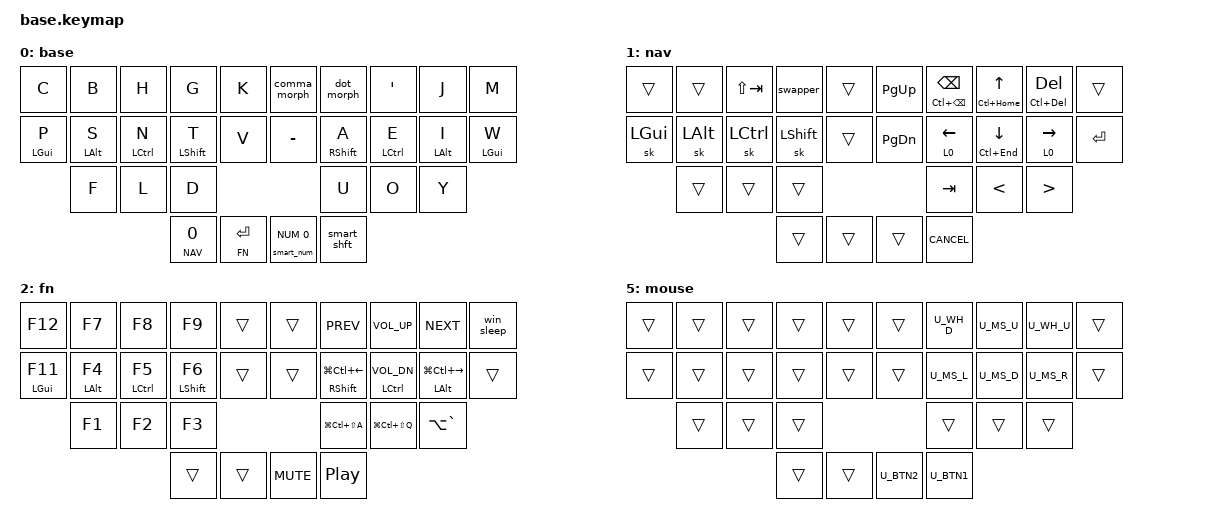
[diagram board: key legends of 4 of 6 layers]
#include <behaviors.dtsi>
#include <dt-bindings/zmk/keys.h>
#if CONFIG_WIRELESS
    #include <dt-bindings/zmk/bt.h>
    #define _BT_SEL_KEYS_ &bt BT_SEL 0 &bt BT_SEL 1 &bt BT_SEL 2 &bt BT_SEL 3 &bt BT_CLR
#else
    #define _BT_SEL_KEYS_ &trans &trans &trans &trans &trans
#endif

#include "../zmk-nodefree-config/helper.h"
// #include "../zmk-nodefree-config/international_chars/greek.dtsi"
// #include "../zmk-nodefree-config/international_chars/german.dtsi"

#define DEF 0
#define NAV 1
#define FN 2
#define NUM 3
#define SYS 4
#define UC 5
#define MOUSE 6

// #include "combos.dtsi"  // requires layer aliases
#include "mouse.dtsi"
#include "extra_keys.h"

#define XXX &none
#define ___ &trans

/* Global settings */

#define QUICK_TAP_MS 175

&sk {  // sticky-key config
    release-after-ms = <900>;  // release after 0.6s
    quick-release;             // no double capitalization when rolling keys
};

&sl {  // sticky-layer config
    ignore-modifiers;          // allow chording sticky mods & layers
};

&lt {  // layer-tap config
    flavor = "balanced";
    tapping-term-ms = <200>;
    quick-tap-ms = <QUICK_TAP_MS>;
};

/* Homerow mods */

#define KEYS_L LT0 LT1 LT2 LT3 LT4 LM0 LM1 LM2 LM3 LM4 LB0 LB1 LB2  // left hand
#define KEYS_R RT0 RT1 RT2 RT3 RT4 RM0 RM1 RM2 RM3 RM4 RB0 RB1 RB2  // right hand
#define THUMBS LH1 LH0 RH0 RH1                                      // thumbs

#define MAKE_HRM(NAME, HOLD, TAP, TRIGGER_POS) \
    ZMK_BEHAVIOR(NAME, hold_tap, \
        flavor = "balanced"; \
        tapping-term-ms = <280>; \
        quick-tap-ms = <QUICK_TAP_MS>; \
        require-prior-idle-ms = <150>; \
        bindings = <HOLD>, <TAP>; \
        hold-trigger-key-positions = <TRIGGER_POS>; \
        hold-trigger-on-release; \
    )
MAKE_HRM(hml, &kp, &kp, KEYS_R THUMBS)  // left-hand HRMs
MAKE_HRM(hmr, &kp, &kp, KEYS_L THUMBS)  // right-hand HRMs

MAKE_HRM(hml_repeat, &kp, &key_repeat, KEYS_R THUMBS)  // used for HRM-combo
MAKE_HRM(hmr_lpar_lt, &kp, &lpar_lt, KEYS_L THUMBS)    // "    "   "   "
MAKE_HRM(hmr_rpar_gt, &kp, &rpar_gt, KEYS_L THUMBS)    // "    "   "   "

/* Nav cluster */

// long-tap action on hold, short-tap action on all interrupts
#define MT_CORE \
    flavor = "tap-preferred"; \
    tapping-term-ms = <220>; \
    quick-tap-ms = <220>; \
    hold-trigger-key-positions = <0>;

&mt { MT_CORE };
ZMK_BEHAVIOR(mt_home, hold_tap, bindings = <&masked_home>, <&kp>; MT_CORE)
ZMK_BEHAVIOR(mt_end,  hold_tap,  bindings = <&masked_end>, <&kp>; MT_CORE)

#define NAV_LEFT  &mt_home 0   LEFT    // tap: left  | long-tap: beginning of line
#define NAV_RIGHT &mt_end 0    RIGHT   // tap: right | long-tap: end       of line
#define NAV_UP    &mt LC(HOME) UP      // tap: up    | long-tap: beginning of document
#define NAV_DOWN  &mt LC(END)  DOWN    // tap: down  | long-tap: end       of document
#define NAV_BSPC  &mt LC(BSPC) BSPC    // tap: bspc  | long-tap: delete word backward
#define NAV_DEL   &mt LC(DEL)  DEL     // tap: del   | long-tap: delete word forward

// mask CTRL when holding left/right to avoid accidental jumps to beginning/end of document
#define MASK_MODS(NAME, MODS, BINDING) \
    ZMK_BEHAVIOR(NAME, mod_morph, \
        bindings = <BINDING>, <BINDING>; \
        mods = <MODS>; \
    )
MASK_MODS(masked_home, (MOD_LCTL), &kp HOME)
MASK_MODS(masked_end,  (MOD_LCTL), &kp END)

/* Caps-word, num-word and smart-mouse */

// tap: sticky-shift | shift + tap/ double-tap: caps-word | hold: shift
ZMK_BEHAVIOR(smart_shft, mod_morph,
    bindings = <&sk LSHFT>, <&caps_word>;
    mods = <(MOD_LSFT)>;
)
&caps_word {  // mods deactivate caps-word, requires PR #1451
    /delete-property/ ignore-modifiers;
};

// tap: num-word | double-tap: sticky num-layer | hold: num-layer
#define SMART_NUM &smart_num NUM 0
ZMK_BEHAVIOR(smart_num, hold_tap,
    flavor = "balanced";
    tapping-term-ms = <200>;
    quick-tap-ms = <QUICK_TAP_MS>;
    bindings = <&mo>, <&num_dance>;
)
ZMK_BEHAVIOR(num_dance, tap_dance,
    tapping-term-ms = <200>;
    bindings = <&num_word>, <&sl NUM>;  // reverse this for sticky-num on single tap
)
&num_word {  // num-word, requires PR #1451
    layers = <NUM>;
    continue-list = <BSPC DEL DOT COMMA PLUS MINUS STAR FSLH EQUAL>;
};

// smart-mouse, requires PR #1366
ZMK_BEHAVIOR(smart_mouse, tri_state,
    bindings = <&tog MOUSE>, <&none>, <&tog MOUSE>;
    ignored-key-positions = <LT1 LT3 RT1 RT2 RT3 RM1 RM2 RM3 RH0 RH1>;
    ignored-layers = <MOUSE>;
)

/* Custom behaviors */

// Alt+Tab swapper, requires PR #1366
ZMK_BEHAVIOR(swapper, tri_state,
    bindings = <&kt LALT>, <&kp TAB>, <&kt LALT>;
    ignored-key-positions = <LT2>;
)

// Sticky layer + sticky shift (workaround for issue #1421)
ZMK_BEHAVIOR(sls, sticky_key,
    release-after-ms = <1000>;
    bindings = <&uc_shift>;
    ignore-modifiers;
)
ZMK_BEHAVIOR(uc_shift, macro,
    wait-ms = <0>;
    tap-ms = <1>;
    bindings = <&macro_press &mo UC &kp LSHFT>
             , <&macro_pause_for_release>
             , <&macro_release &mo UC &kp LSHFT>;
)

// reuse basic mod-morph scheme
#define SIMPLE_MORPH(NAME, MOD, BINDING1, BINDING2) \
    ZMK_BEHAVIOR(NAME, mod_morph, \
        mods = <(MOD_L ## MOD|MOD_R ## MOD)>; \
        bindings = <BINDING1>, <BINDING2>; \
    )

// tap: comma | shift + tap: semicolon | ctrl + shift + tap: <
SIMPLE_MORPH(comma_morph, SFT, &kp COMMA, &comma_inner_morph)
SIMPLE_MORPH(comma_inner_morph, CTL, &kp SEMICOLON, &kp LESS_THAN)

// tap: dot | shift + tap: colon | ctrl + shift + tap: >
SIMPLE_MORPH(dot_morph, SFT, &kp DOT, &dot_inner_morph)
SIMPLE_MORPH(dot_inner_morph, CTL, &kp COLON, &kp GREATER_THAN)

// tap: qmark | shift + tap: excl
SIMPLE_MORPH(qexcl, SFT, &kp QMARK, &kp EXCL)

// tap: left/right parenthesis | shft + tap: less-than/greater-than
SIMPLE_MORPH(lpar_lt, SFT, &kp LPAR, &kp LT)
SIMPLE_MORPH(rpar_gt, SFT, &kp RPAR, &kp GT)

// tap: space | shift + tap: dot -> space -> sticky shift | hold: activate layer
ZMK_BEHAVIOR(lt_spc, hold_tap,
    flavor = "balanced";
    tapping-term-ms = <200>;
    quick-tap-ms = <QUICK_TAP_MS>;
    bindings = <&mo>, <&spc_morph>;
)
SIMPLE_MORPH(spc_morph, SFT, &kp SPACE, &dot_spc)
ZMK_BEHAVIOR(dot_spc, macro,
    wait-ms = <0>;
    tap-ms = <5>;
    bindings = <&kp DOT &kp SPACE &sk LSHFT>;
)

// tap: backspace | lshft + tap: delete | rshft + tap: shift-delete
ZMK_BEHAVIOR(bs_del, mod_morph,
    bindings = <&kp BSPC>, <&kp DEL>;
    mods = <(MOD_LSFT|MOD_RSFT)>;
    keep-mods = <MOD_RSFT>;
)

// tap: copy | double-tap: cut
ZMK_BEHAVIOR(copy_cut, tap_dance,
    tapping-term-ms = <200>;
    bindings = <&kp LC(INS)>, <&kp LC(X)>;
)

// Windows sleep key
ZMK_BEHAVIOR(win_sleep, macro,
    wait-ms = <500>;
    tap-ms = <50>;
    bindings = <&kp LG(X) &kp U &kp S>;
)

// misc aliases
#define CANCEL      &kp K_CANCEL             // cancel caps-word, num-word and smart-mouse
#define DSK_PREV    &hmr RSHFT LG(LC(LEFT))  // previous desktop
#define DSK_NEXT    &hmr LALT LG(LC(RIGHT))  // next     desktop
#define PIN_WIN     &kp LG(LC(LS(Q)))        // pin window across desktops
#define PIN_APP     &kp LG(LC(LS(A)))        // pin application across desktops
#define DSK_MGR     &kp LA(GRAVE)            // desktop manager
#define VOL_DOWN    &hmr LCTRL C_VOL_DN

/* Keymap */

ZMK_CONDITIONAL_LAYER(FN NUM, SYS)  // FN + NUM --> SYS

ZMK_LAYER(base,
// ╭─────────────┬─────────────┬─────────────┬─────────────┬─────────────╮  ╭─────────────┬─────────────┬─────────────┬─────────────┬─────────────╮
     &kp C         &kp B         &kp H         &kp G         &kp K            &comma_morph  &dot_morph    &kp SQT       &kp J         &kp M        
// ├─────────────┼─────────────┼─────────────┼─────────────┼─────────────┤  ├─────────────┼─────────────┼─────────────┼─────────────┼─────────────┤
     &hml LGUI P   &hml LALT S   &hml LCTRL N  &hml LSHFT T  &kp V            &kp MINUS     &hmr RSHFT A  &hmr LCTRL E  &hmr LALT I   &hmr LGUI W  
// ├─────────────┼─────────────┼─────────────┼─────────────┼─────────────┤  ├─────────────┼─────────────┼─────────────┼─────────────┼─────────────┤
                   &kp F         &kp L         &kp D                                        &kp U         &kp O         &kp Y                      
// ╰─────────────┼─────────────┴─────────────┼─────────────┼─────────────┤  ├─────────────┼─────────────┼─────────────┴─────────────┴─────────────╯
                                               &lt_spc NAV 0 &lt FN RET       SMART_NUM     &smart_shft                                            
//                                           ╰─────────────┴─────────────╯  ╰─────────────┴─────────────╯                                          
)

ZMK_LAYER(nav,
// ╭─────────────┬─────────────┬─────────────┬─────────────┬─────────────╮  ╭─────────────┬─────────────┬─────────────┬─────────────┬─────────────╮
     ___           ___           &kp LS(TAB)   &swapper      ___              &kp PG_UP     NAV_BSPC      NAV_UP        NAV_DEL       ___          
// ├─────────────┼─────────────┼─────────────┼─────────────┼─────────────┤  ├─────────────┼─────────────┼─────────────┼─────────────┼─────────────┤
     &sk LGUI      &sk LALT      &sk LCTRL     &sk LSHFT     ___              &kp PG_DN     NAV_LEFT      NAV_DOWN      NAV_RIGHT     &kp RET      
// ├─────────────┼─────────────┼─────────────┼─────────────┼─────────────┤  ├─────────────┼─────────────┼─────────────┼─────────────┼─────────────┤
                   ___           ___           ___                                          &kp TAB       &kp LT        &kp GT                     
// ╰─────────────┼─────────────┴─────────────┼─────────────┼─────────────┤  ├─────────────┼─────────────┼─────────────┴─────────────┴─────────────╯
                                               ___           ___              ___           CANCEL                                                 
//                                           ╰─────────────┴─────────────╯  ╰─────────────┴─────────────╯                                          
)  

ZMK_LAYER(fn,
// ╭─────────────┬─────────────┬─────────────┬─────────────┬─────────────╮  ╭─────────────┬─────────────┬─────────────┬─────────────┬─────────────╮
     &kp F12       &kp F7        &kp F8        &kp F9        ___              ___           &kp C_PREV    &kp C_VOL_UP  &kp C_NEXT    &win_sleep   
// ├─────────────┼─────────────┼─────────────┼─────────────┼─────────────┤  ├─────────────┼─────────────┼─────────────┼─────────────┼─────────────┤
     &hml LGUI F11 &hml LALT F4  &hml LCTRL F5 &hml LSHFT F6 ___              ___           DSK_PREV      VOL_DOWN      DSK_NEXT      ___          
// ├─────────────┼─────────────┼─────────────┼─────────────┼─────────────┤  ├─────────────┼─────────────┼─────────────┼─────────────┼─────────────┤
                   &kp F1        &kp F2        &kp F3                                       PIN_APP       PIN_WIN       DSK_MGR             
// ╰─────────────┼─────────────┴─────────────┼─────────────┼─────────────┤  ├─────────────┼─────────────┼─────────────┴─────────────┴─────────────╯
                                               ___           ___              &kp C_MUTE    &kp C_PP                                               
//                                           ╰─────────────┴─────────────╯  ╰─────────────┴─────────────╯                                          
)

ZMK_LAYER(num,
// ╭─────────────┬─────────────┬─────────────┬─────────────┬─────────────╮  ╭─────────────┬─────────────┬─────────────┬─────────────┬─────────────╮
     ___           &kp N7        &kp N8        &kp N9        ___              ___           ___           ___           ___           ___          
// ├─────────────┼─────────────┼─────────────┼─────────────┼─────────────┤  ├─────────────┼─────────────┼─────────────┼─────────────┼─────────────┤
     &hml LGUI N0  &hml LALT N4  &hml LCTRL N5 &hml LSHFT N6 ___              ___           ___           ___           ___           ___          
// ├─────────────┼─────────────┼─────────────┼─────────────┼─────────────┤  ├─────────────┼─────────────┼─────────────┼─────────────┼─────────────┤
                   &kp N1        &kp N2        &kp N3                         ___           ___           ___           ___           
// ╰─────────────┼─────────────┴─────────────┼─────────────┼─────────────┤  ├─────────────┼─────────────┼─────────────┴─────────────┴─────────────╯
                                               ___           ___              ___           ___                                                    
//                                           ╰─────────────┴─────────────╯  ╰─────────────┴─────────────╯                                          
)

ZMK_LAYER(sys,
// ╭─────────────┬─────────────┬─────────────┬─────────────┬─────────────╮  ╭─────────────┬─────────────┬─────────────┬─────────────┬─────────────╮
                                _BT_SEL_KEYS_                                 ___           ___           ___           ___           ___          
// ├─────────────┼─────────────┼─────────────┼─────────────┼─────────────┤  ├─────────────┼─────────────┼─────────────┼─────────────┼─────────────┤
     ___           ___           ___           ___           &bootloader      &bootloader   ___           ___           ___           ___          
// ├─────────────┼─────────────┼─────────────┼─────────────┼─────────────┤  ├─────────────┼─────────────┼─────────────┼─────────────┼─────────────┤
                   ___           ___           &sys_reset                                   &sys_reset    ___           ___           
// ╰─────────────┼─────────────┴─────────────┼─────────────┼─────────────┤  ├─────────────┼─────────────┼─────────────┴─────────────┴─────────────╯
                                               ___           ___              ___           ___                                                    
//                                           ╰─────────────┴─────────────╯  ╰─────────────┴─────────────╯                                          
)

ZMK_LAYER(mouse,
// ╭─────────────┬─────────────┬─────────────┬─────────────┬─────────────╮  ╭─────────────┬─────────────┬─────────────┬─────────────┬─────────────╮
     ___           ___           ___           ___           ___              ___           U_WH_D        U_MS_U         U_WH_U       ___          
// ├─────────────┼─────────────┼─────────────┼─────────────┼─────────────┤  ├─────────────┼─────────────┼─────────────┼─────────────┼─────────────┤
     ___           ___           ___           ___           ___              ___           U_MS_L        U_MS_D         U_MS_R       ___          
// ├─────────────┼─────────────┼─────────────┼─────────────┼─────────────┤  ├─────────────┼─────────────┼─────────────┼─────────────┼─────────────┤
                   ___           ___           ___                                          ___           ___            ___        
// ╰─────────────┼─────────────┴─────────────┼─────────────┼─────────────┤  ├─────────────┼─────────────┼─────────────┴─────────────┴─────────────╯
                                               ___           ___              U_BTN2        U_BTN1                                                 
//                                           ╰─────────────┴─────────────╯  ╰─────────────┴─────────────╯                                          
)

/* vim: set ft=c tw=174: */
